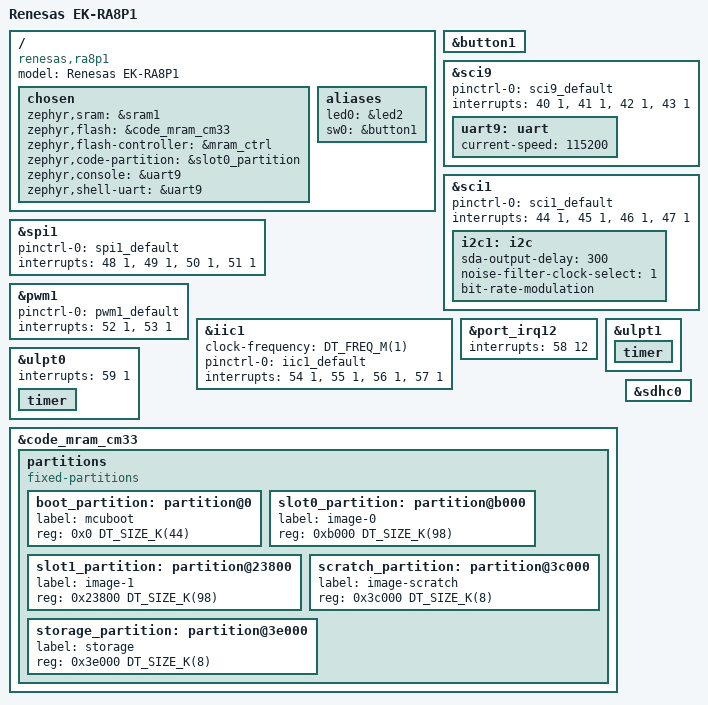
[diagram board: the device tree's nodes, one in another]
/*
 * Copyright (c) 2025 Renesas Electronics Corporation
 * SPDX-License-Identifier: Apache-2.0
 */

/dts-v1/;

#include <renesas/ra/ra8/r7ka8p1kflcac_cm33.dtsi>
#include "ek_ra8p1.dtsi"

/ {
	model = "Renesas EK-RA8P1";
	compatible = "renesas,ra8p1", "renesas,ra8";

	chosen {
		zephyr,sram = &sram1;
		zephyr,flash = &code_mram_cm33;
		zephyr,flash-controller = &mram_ctrl;
		zephyr,code-partition = &slot0_partition;
		zephyr,console = &uart9;
		zephyr,shell-uart = &uart9;
	};

	aliases {
		led0 = &led2;
		sw0 = &button1;
	};
};

&button1 {
	status = "okay";
};

&sci9 {
	pinctrl-0 = <&sci9_default>;
	pinctrl-names = "default";
	interrupts = <40 1>, <41 1>, <42 1>, <43 1>;
	interrupt-names = "rxi", "txi", "tei", "eri";
	status = "okay";

	uart9: uart {
		current-speed = <115200>;
		status = "okay";
	};
};

&sci1 {
	pinctrl-0 = <&sci1_default>;
	pinctrl-names = "default";
	interrupts = <44 1>, <45 1>, <46 1>, <47 1>;
	interrupt-names = "rxi", "txi", "tei", "eri";

	i2c1: i2c {
		sda-output-delay = <300>;
		noise-filter-clock-select = <1>;
		bit-rate-modulation;
	};
};

&spi1 {
	pinctrl-0 = <&spi1_default>;
	pinctrl-names = "default";
	interrupts = <48 1>, <49 1>, <50 1>, <51 1>;
	interrupt-names = "rxi", "txi", "tei", "eri";
	status = "okay";
};

&pwm1 {
	pinctrl-0 = <&pwm1_default>;
	interrupts = <52 1>, <53 1>;
	interrupt-names = "gtioca", "overflow";
	pinctrl-names = "default";
	status = "okay";
};

&iic1 {
	#address-cells = <1>;
	#size-cells = <0>;
	clock-frequency = <DT_FREQ_M(1)>;
	pinctrl-0 = <&iic1_default>;
	pinctrl-names = "default";
	interrupts = <54 1>, <55 1>, <56 1>, <57 1>;
	interrupt-names = "rxi", "txi", "tei", "eri";
	status = "okay";
};

&port_irq12 {
	interrupts = <58 12>;
	status = "okay";
};

&ulpt0 {
	interrupts = <59 1>;
	interrupt-names = "ulpti";
	status = "okay";

	timer {
		status = "okay";
	};
};

&ulpt1 {
	status = "okay";

	timer {
		status = "okay";
	};
};

&code_mram_cm33 {
	partitions {
		compatible = "fixed-partitions";
		#address-cells = <1>;
		#size-cells = <1>;

		boot_partition: partition@0 {
			label = "mcuboot";
			reg = <0x0 DT_SIZE_K(44)>;
		};

		slot0_partition: partition@b000 {
			label = "image-0";
			reg = <0xb000 DT_SIZE_K(98)>;
		};

		slot1_partition: partition@23800 {
			label = "image-1";
			reg = <0x23800 DT_SIZE_K(98)>;
		};

		scratch_partition: partition@3c000 {
			label = "image-scratch";
			reg = <0x3c000 DT_SIZE_K(8)>;
		};

		storage_partition: partition@3e000 {
			label = "storage";
			reg = <0x3e000 DT_SIZE_K(8)>;
		};
	};
};

pmod_sd_shield: &sdhc0 {};
